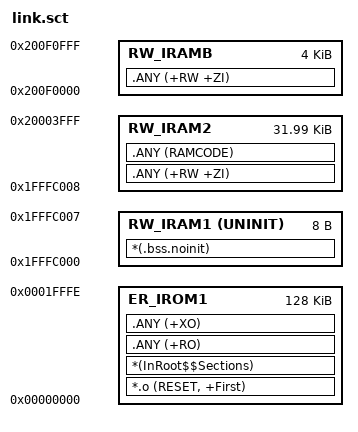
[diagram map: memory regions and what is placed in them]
; ****************************************************************
; Scatter-Loading Description File
; ****************************************************************
LR_IROM1 0x00000000 0x0001FFFF  {    ; load region size_region
    ER_IROM1 0x00000000 0x0001FFFF  {  ; load address = execution address
        *.o (RESET, +First)
        *(InRoot$$Sections)
        .ANY (+RO)
        .ANY (+XO)
    }
    RW_IRAM1 0x1FFFC000  UNINIT 0x00000008   {  ; RW data
        *(.bss.noinit)
    }
    RW_IRAM2 0x1FFFC008  0x00007FF8   {  ; RW data
        .ANY (+RW +ZI)
        .ANY (RAMCODE)
    }
    RW_IRAMB 0x200F0000 0x00001000  {  ; RW data
        .ANY (+RW +ZI)
    }
}

